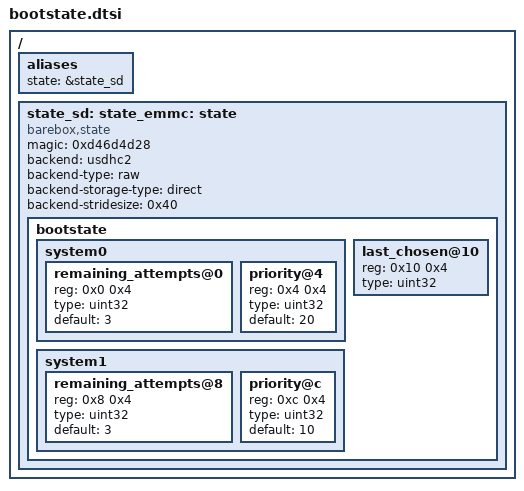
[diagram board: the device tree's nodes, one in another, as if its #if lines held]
/** Radxa ROCK3 Model A *******************************************************/
#ifdef rk3568_rock_3a_dts
/ {
	aliases {
		state = &state_sd;
	};

	state_sd: state {
		#address-cells = <1>;
		#size-cells = <1>;
		compatible = "barebox,state";
		magic = <0xde3e5c14>;
		backend = <&sdmmc0>;   // via GPT Type UUID
		backend-type = "raw";
		backend-storage-type = "direct";
		backend-stridesize = <0x40>;
	};
};

#endif

/** TQ-Systems i.MX8MPlus TQMa8MPxL on MBa8MPxL *******************************/
#ifdef imx8mp_tqma8mpql_mba8mpxl_dts
/ {
	aliases {
		state = &state_sd;
	};

	state_sd: state {
		#address-cells = <1>;
		#size-cells = <1>;
		compatible = "barebox,state";
		magic = <0x5e4d20bf>;
		backend = <&usdhc2>;   // via GPT Type UUID
		backend-type = "raw";
		backend-storage-type = "direct";
		backend-stridesize = <0x40>;
	};
};

#endif

/** BeagleBoard BeaglePlay with TI Sitara AM625 *******************************/
#ifdef k3_am625_beagleplay_dts
/ {
	aliases {
		state = &state_emmc;
	};

	state_emmc: state {
		#address-cells = <1>;
		#size-cells = <1>;
		compatible = "barebox,state";
		magic = <0x444f1d39>;
		backend = <&sdhci1>;   // via GPT Type UUID
		backend-type = "raw";
		backend-storage-type = "direct";
		backend-stridesize = <0x40>;
	};
};

#endif

/** TQ-Systems i.MX93 TQMa93xxLA/TQMa93xxCA on MBa93xxCA starter kit **********/
#ifdef imx93_tqma9352_mba93xxca_dts
/ {
	aliases {
		state = &state_sd;
	};

	state_sd: state {
		#address-cells = <1>;
		#size-cells = <1>;
		compatible = "barebox,state";
		magic = <0xd46d4d28>;
		backend = <&usdhc2>;   // via GPT Type UUID
		backend-type = "raw";
		backend-storage-type = "direct";
		backend-stridesize = <0x40>;
	};
};

#endif

/** Generic bootstate node for all platforms **********************************/
/ {
	state: state {
		bootstate: bootstate {};
	};
};

&bootstate {
	#address-cells = <1>;
	#size-cells = <1>;

	system0 {
		#address-cells = <1>;
		#size-cells = <1>;

		remaining_attempts@0 {
			reg = <0x0 0x4>;
			type = "uint32";
			default = <3>;
		};

		priority@4 {
			reg = <0x4 0x4>;
			type = "uint32";
			default = <20>;
		};
	};

	system1 {
		#address-cells = <1>;
		#size-cells = <1>;

		remaining_attempts@8 {
			reg = <0x8 0x4>;
			type = "uint32";
			default = <3>;
		};

		priority@c {
			reg = <0xc 0x4>;
			type = "uint32";
			default = <10>;
		};
	};

	last_chosen@10 {
		reg = <0x10 0x4>;
		type = "uint32";
	};
};
